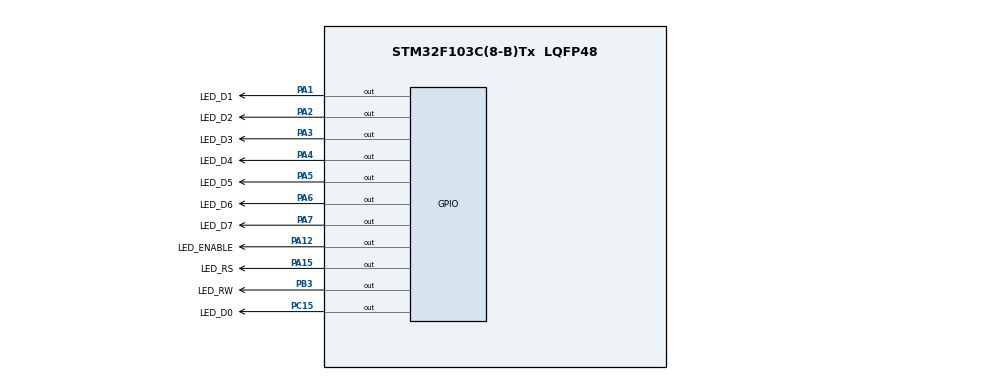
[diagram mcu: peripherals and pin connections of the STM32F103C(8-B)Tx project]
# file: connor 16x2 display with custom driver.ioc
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Mcu.Family=STM32F1
Mcu.Name=STM32F103C(8-B)Tx
Mcu.Package=LQFP48
NVIC.PriorityGroup=NVIC_PRIORITYGROUP_4
PA1.GPIO_Label=LED_D1
PA1.GPIO_Speed=GPIO_SPEED_FREQ_HIGH
PA1.Signal=GPIO_Output
PA12.GPIO_Label=LED_ENABLE
PA12.Signal=GPIO_Output
PA15.GPIO_Label=LED_RS
PA15.Signal=GPIO_Output
PA2.GPIO_Label=LED_D2
PA2.GPIO_Speed=GPIO_SPEED_FREQ_HIGH
PA2.Signal=GPIO_Output
PA3.GPIO_Label=LED_D3
PA3.GPIO_Speed=GPIO_SPEED_FREQ_HIGH
PA3.Signal=GPIO_Output
PA4.GPIO_Label=LED_D4
PA4.GPIO_Speed=GPIO_SPEED_FREQ_HIGH
PA4.Signal=GPIO_Output
PA5.GPIO_Label=LED_D5
PA5.GPIO_Speed=GPIO_SPEED_FREQ_HIGH
PA5.Signal=GPIO_Output
PA6.GPIO_Label=LED_D6
PA6.GPIO_Speed=GPIO_SPEED_FREQ_HIGH
PA6.Signal=GPIO_Output
PA7.GPIO_Label=LED_D7
PA7.GPIO_Speed=GPIO_SPEED_FREQ_HIGH
PA7.Signal=GPIO_Output
PB3.GPIO_Label=LED_RW
PB3.Signal=GPIO_Output
PC15-OSC32_OUT.GPIO_Label=LED_D0
PC15-OSC32_OUT.GPIO_Speed=GPIO_SPEED_FREQ_HIGH
PC15-OSC32_OUT.Signal=GPIO_Output
ProjectManager.HeapSize=0x200
ProjectManager.StackSize=0x400
ProjectManager.TargetToolchain=Makefile
RCC.APB1Freq_Value=8000000
RCC.APB2Freq_Value=8000000
VP_SYS_VS_ND.Mode=No_Debug
board=custom

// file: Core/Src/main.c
/* USER CODE BEGIN Header */
/**
  ******************************************************************************
  * @file           : main.c
  * @brief          : Main program body
  ******************************************************************************
  * @attention
  *
  * Copyright (c) 2023 STMicroelectronics.
  * All rights reserved.
  *
  * This software is licensed under terms that can be found in the LICENSE file
  * in the root directory of this software component.
  * If no LICENSE file comes with this software, it is provided AS-IS.
  *
  ******************************************************************************
  */
/* USER CODE END Header */
#include "main.h"

/* USER CODE BEGIN Includes */
#include "16x2.h"
/* USER CODE END Includes */

void SystemClock_Config(void);
static void MX_GPIO_Init(void);

int main(void)
{

  /* MCU Configuration--------------------------------------------------------*/

  /* Reset of all peripherals, Initializes the Flash interface and the Systick. */
  HAL_Init();

  /* Configure the system clock */
  SystemClock_Config();

  /* Initialize all configured peripherals */
  MX_GPIO_Init();

  /* Infinite loop */
  while (1)
  {

  }
}

void SystemClock_Config(void)
{
  RCC_OscInitTypeDef RCC_OscInitStruct = {0};
  RCC_ClkInitTypeDef RCC_ClkInitStruct = {0};

  /** Initializes the RCC Oscillators according to the specified parameters
  * in the RCC_OscInitTypeDef structure.
  */
  RCC_OscInitStruct.OscillatorType = RCC_OSCILLATORTYPE_HSI;
  RCC_OscInitStruct.HSIState = RCC_HSI_ON;
  RCC_OscInitStruct.HSICalibrationValue = RCC_HSICALIBRATION_DEFAULT;
  RCC_OscInitStruct.PLL.PLLState = RCC_PLL_NONE;
  if (HAL_RCC_OscConfig(&RCC_OscInitStruct) != HAL_OK)
  {
    Error_Handler();
  }

  /** Initializes the CPU, AHB and APB buses clocks
  */
  RCC_ClkInitStruct.ClockType = RCC_CLOCKTYPE_HCLK|RCC_CLOCKTYPE_SYSCLK
                              |RCC_CLOCKTYPE_PCLK1|RCC_CLOCKTYPE_PCLK2;
  RCC_ClkInitStruct.SYSCLKSource = RCC_SYSCLKSOURCE_HSI;
  RCC_ClkInitStruct.AHBCLKDivider = RCC_SYSCLK_DIV1;
  RCC_ClkInitStruct.APB1CLKDivider = RCC_HCLK_DIV1;
  RCC_ClkInitStruct.APB2CLKDivider = RCC_HCLK_DIV1;

  if (HAL_RCC_ClockConfig(&RCC_ClkInitStruct, FLASH_LATENCY_0) != HAL_OK)
  {
    Error_Handler();
  }
}

static void MX_GPIO_Init(void)
{
  GPIO_InitTypeDef GPIO_InitStruct = {0};

  /* GPIO Ports Clock Enable */
  __HAL_RCC_GPIOC_CLK_ENABLE();
  __HAL_RCC_GPIOA_CLK_ENABLE();
  __HAL_RCC_GPIOB_CLK_ENABLE();

  /*Configure GPIO pin Output Level */
  HAL_GPIO_WritePin(LED_D0_GPIO_Port, LED_D0_Pin, GPIO_PIN_RESET);

  /*Configure GPIO pin Output Level */
  HAL_GPIO_WritePin(GPIOA, LED_D1_Pin|LED_D2_Pin|LED_D3_Pin|LED_D4_Pin
                          |LED_D5_Pin|LED_D6_Pin|LED_D7_Pin|LED_ENABLE_Pin
                          |LED_RS_Pin, GPIO_PIN_RESET);

  /*Configure GPIO pin Output Level */
  HAL_GPIO_WritePin(LED_RW_GPIO_Port, LED_RW_Pin, GPIO_PIN_RESET);

  /*Configure GPIO pin : LED_D0_Pin */
  GPIO_InitStruct.Pin = LED_D0_Pin;
  GPIO_InitStruct.Mode = GPIO_MODE_OUTPUT_PP;
  GPIO_InitStruct.Pull = GPIO_NOPULL;
  GPIO_InitStruct.Speed = GPIO_SPEED_FREQ_HIGH;
  HAL_GPIO_Init(LED_D0_GPIO_Port, &GPIO_InitStruct);

  /*Configure GPIO pins : LED_D1_Pin LED_D2_Pin LED_D3_Pin LED_D4_Pin
                           LED_D5_Pin LED_D6_Pin LED_D7_Pin */
  GPIO_InitStruct.Pin = LED_D1_Pin|LED_D2_Pin|LED_D3_Pin|LED_D4_Pin
                          |LED_D5_Pin|LED_D6_Pin|LED_D7_Pin;
  GPIO_InitStruct.Mode = GPIO_MODE_OUTPUT_PP;
  GPIO_InitStruct.Pull = GPIO_NOPULL;
  GPIO_InitStruct.Speed = GPIO_SPEED_FREQ_HIGH;
  HAL_GPIO_Init(GPIOA, &GPIO_InitStruct);

  /*Configure GPIO pins : LED_ENABLE_Pin LED_RS_Pin */
  GPIO_InitStruct.Pin = LED_ENABLE_Pin|LED_RS_Pin;
  GPIO_InitStruct.Mode = GPIO_MODE_OUTPUT_PP;
  GPIO_InitStruct.Pull = GPIO_NOPULL;
  GPIO_InitStruct.Speed = GPIO_SPEED_FREQ_LOW;
  HAL_GPIO_Init(GPIOA, &GPIO_InitStruct);

  /*Configure GPIO pin : LED_RW_Pin */
  GPIO_InitStruct.Pin = LED_RW_Pin;
  GPIO_InitStruct.Mode = GPIO_MODE_OUTPUT_PP;
  GPIO_InitStruct.Pull = GPIO_NOPULL;
  GPIO_InitStruct.Speed = GPIO_SPEED_FREQ_LOW;
  HAL_GPIO_Init(LED_RW_GPIO_Port, &GPIO_InitStruct);

}

void Error_Handler(void)
{
  __disable_irq();
  while (1)
  {
  }
}
